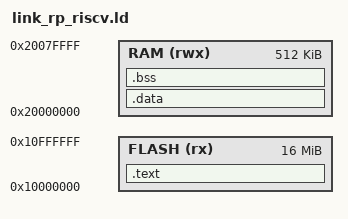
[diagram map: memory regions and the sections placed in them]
OUTPUT_ARCH("riscv")
ENTRY(_start)

MEMORY
{
    FLASH (rx)  : ORIGIN = 0x10000000, LENGTH = 16M
    RAM   (rwx) : ORIGIN = 0x20000000, LENGTH = 512K
}

SECTIONS
{
    .text : {
        KEEP(*(.text.start))
        *(.text .text.*)
        *(.rodata .rodata.*)
    } > FLASH
    .data : {
        *(.data .data.*)
        *(.sdata .sdata.*)
        PROVIDE(__global_pointer$ = . + 0x800);
    } > RAM
    .bss (NOLOAD) : ALIGN(4) {
        __bss_start = .;
        *(.bss .bss.*)
        *(.sbss .sbss.*)
        *(COMMON)
        . = ALIGN(4);
        __bss_end = .;
    } > RAM
}
